# ARMv7-M-ETM register map
Registers from a debugger description file.
Registers are 32-bit, read-only, no defined reset value unless marked. A register's access mark holds for its fields unless they carry their own. Addresses are absolute; registers are grouped by the start of their names; lines under a group give offsets from that group; [hi:lo] are bit positions; {n}, {i} and the like mark numbered series; 'fields as' and 'values as' point back to an identical list; <NAME> marks a mode.

## ETM
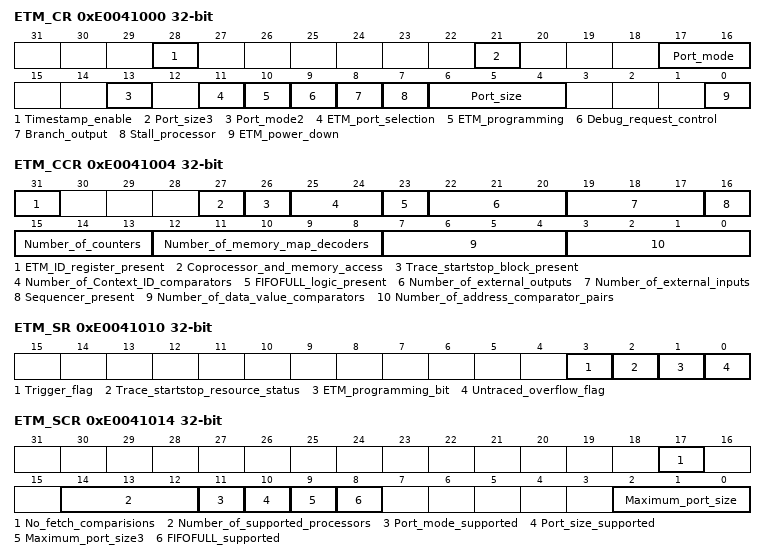
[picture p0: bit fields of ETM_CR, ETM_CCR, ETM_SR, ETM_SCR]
0xE0041000 ETM_CR access not given
  [28] Timestamp_enable, [21] Port_size3, [17:16] Port_mode, [13] Port_mode2, [11] ETM_port_selection, [10] ETM_programming, [9] Debug_request_control, [8] Branch_output, [7] Stall_processor, [6:4] Port_size, [0] ETM_power_down
0xE0041004 ETM_CCR
  [31] ETM_ID_register_present, [27] Coprocessor_and_memory_access, [26] Trace_startstop_block_present, [25:24] Number_of_Context_ID_comparators, [23] FIFOFULL_logic_present, [22:20] Number_of_external_outputs, [19:17] Number_of_external_inputs, [16] Sequencer_present, [15:13] Number_of_counters, [12:8] Number_of_memory_map_decoders, [7:4] Number_of_data_value_comparators, [3:0] Number_of_address_comparator_pairs
0xE0041008 ETM_TRIGGER access not given
  [16:14] Function, [13:11] Resource_B_Type, [10:7] Resource_B_Index, [6:4] Resource_A_Type, [16:0] Trigger_event, [3:0] Resource_A_Index
0xE0041010 ETM_SR access not given
  [3] Trigger_flag, [2] Trace_startstop_resource_status, [1] ETM_programming_bit, [0] Untraced_overflow_flag
0xE0041014 ETM_SCR
  [17] No_fetch_comparisions, [14:12] Number_of_supported_processors, [11] Port_mode_supported, [10] Port_size_supported, [9] Maximum_port_size3, [8] FIFOFULL_supported, [2:0] Maximum_port_size
0xE0041020 ETM_TEEVR access not given
  [16:14] Function, [13:11] Resource_B_Type, [10:7] Resource_B_Index, [6:4] Resource_A_Type, [16:0] TraceEnable_event, [3:0] Resource_A_Index
0xE0041024 ETM_TECR1 access not given
  [25] Trace_control_enable
0xE004102C ETM_FFLR access not given
  [7:0] FIFO_full_level
{0xE004113C+4i} ETM_CNTRLDVR{i} access not given (i=1..4)
  [15:0] Initial_count
0xE00411E0 ETM_SYNCFR access not given
  [11:0] Synchronization_frequency
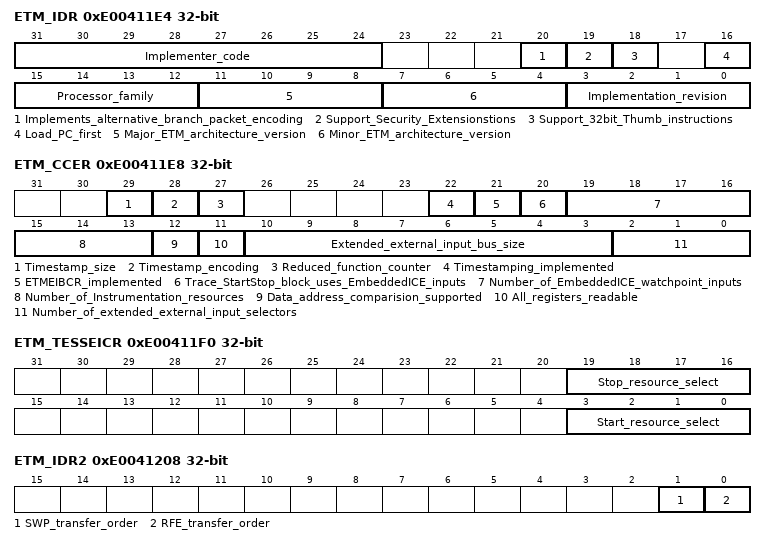
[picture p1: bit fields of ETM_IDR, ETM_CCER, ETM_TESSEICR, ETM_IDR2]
0xE00411E4 ETM_IDR
  [31:24] Implementer_code, [20] Implements_alternative_branch_packet_encoding, [19] Support_Security_Extensionstions, [18] Support_32bit_Thumb_instructions, [16] Load_PC_first, [15:12] Processor_family, [11:8] Major_ETM_architecture_version, [7:4] Minor_ETM_architecture_version, [3:0] Implementation_revision
0xE00411E8 ETM_CCER
  [29] Timestamp_size, [28] Timestamp_encoding, [27] Reduced_function_counter, [22] Timestamping_implemented, [21] ETMEIBCR_implemented, [20] Trace_StartStop_block_uses_EmbeddedICE_inputs, [19:16] Number_of_EmbeddedICE_watchpoint_inputs, [15:13] Number_of_Instrumentation_resources, [12] Data_address_comparision_supported, [11] All_registers_readable, [10:3] Extended_external_input_bus_size, [2:0] Number_of_extended_external_input_selectors
0xE00411F0 ETM_TESSEICR access not given
  [19:16] Stop_resource_select, [3:0] Start_resource_select
0xE00411F8 ETM_TSEVR access not given
  [16:14] Function, [13:11] Resource_B_Type, [10:7] Resource_B_Index, [6:4] Resource_A_Type, [16:0] Timestamp_event, [3:0] Resource_A_Index
0xE0041200 ETM_TRACEIDR access not given
  [6:0] Trace_ID
0xE0041208 ETM_IDR2
  [1] SWP_transfer_order, [0] RFE_transfer_order
0xE0041314 ETM_PDSR access not given
  [0] ETM_powered_up
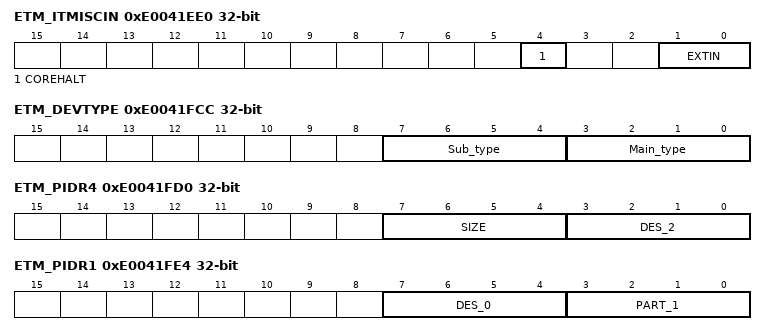
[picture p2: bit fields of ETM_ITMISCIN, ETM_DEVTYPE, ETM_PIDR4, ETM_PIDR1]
0xE0041EE0 ETM_ITMISCIN
  [4] COREHALT, [1:0] EXTIN
0xE0041EE8 ETM_ITTRIGOUT wo
  [0] TRIGGER_output_value
0xE0041F00 ETM_ITCTRL access not given
0xE0041FA0 ETM_CLAIMSET access not given
  [7:0] Tag
0xE0041FA4 ETM_CLAIMCLR access not given
  [7:0] Tag
0xE0041FB0 ETM_LAR wo
0xE0041FB4 ETM_LSR
0xE0041FB8 ETM_AUTHSTATUS
0xE0041FC8 ETM_DEVID
0xE0041FCC ETM_DEVTYPE
  [7:4] Sub_type, [3:0] Main_type
0xE0041FD0 ETM_PIDR4
  [7:4] SIZE, [3:0] DES_2
{0xE0041FC0+4i} ETM_PIDR{i} (i=5..7)
0xE0041FE0 ETM_PIDR0
  [7:0] PART_0
0xE0041FE4 ETM_PIDR1
  [7:4] DES_0, [3:0] PART_1
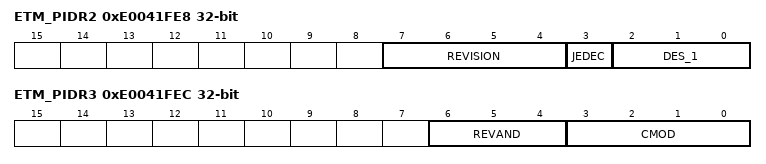
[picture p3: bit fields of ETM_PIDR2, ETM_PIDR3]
0xE0041FE8 ETM_PIDR2
  [7:4] REVISION, [3] JEDEC, [2:0] DES_1
0xE0041FEC ETM_PIDR3
  [6:4] REVAND, [3:0] CMOD
{0xE0041FF0+4i} ETM_CIDR{i} (i=0..3)
